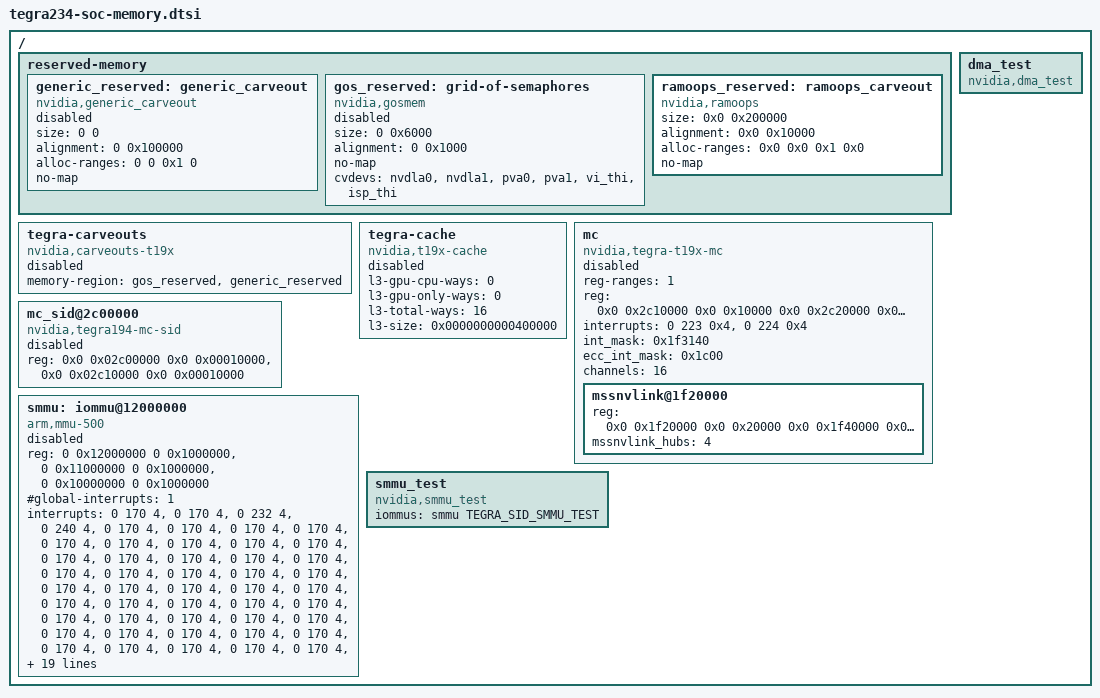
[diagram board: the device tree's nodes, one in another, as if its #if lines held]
/*
 * Copyright (c) 2018, NVIDIA CORPORATION.  All rights reserved.
 *
 * This program is free software; you can redistribute it and/or modify
 * it under the terms of the GNU General Public License as published by
 * the Free Software Foundation; version 2 of the License.
 *
 * This program is distributed in the hope that it will be useful, but WITHOUT
 * ANY WARRANTY; without even the implied warranty of MERCHANTABILITY or
 * FITNESS FOR A PARTICULAR PURPOSE.  See the GNU General Public License for
 * more details.
 *
 */

/ {
	reserved-memory {
		#address-cells = <2>;
		#size-cells = <2>;
		ranges;

		generic_reserved: generic_carveout {
			compatible = "nvidia,generic_carveout";
			size = <0 0>;
			alignment = <0 0x100000>;
			alloc-ranges = <0 0 0x1 0>;
			no-map;
			status = "disabled";
		};

		gos_reserved: grid-of-semaphores {
			compatible = "nvidia,gosmem";
			size = <0 0x6000>;
			alignment = <0 0x1000>;
			no-map;
			status = "disabled";
			cvdevs = <&nvdla0 &nvdla1 &pva0 &pva1 &vi_thi &isp_thi>;
		};

		ramoops_reserved: ramoops_carveout {
			compatible = "nvidia,ramoops";
			size = <0x0 0x200000>;
			alignment = <0x0 0x10000>;
			alloc-ranges = <0x0 0x0 0x1 0x0>;
			no-map;
		};

	};

	tegra-carveouts {
		compatible = "nvidia,carveouts-t19x";
		/* *************Note**************
		 * Zero sized memory regions has to be kept at the end of "memory-region"
		 * array. "memory-region" parser stops parsing other regions in the array
		 * once it finds Zero size "memory-region". Hence keep non zero sized
		 * "memory-region" before the zero sized ones.
		 */
		memory-region = <&gos_reserved &generic_reserved>;
		status = "disabled";
	};

	tegra-cache {
		compatible = "nvidia,t19x-cache";
		l3-gpu-cpu-ways = <0>;
		l3-gpu-only-ways = <0>;
		l3-total-ways = <16>;
		l3-size = /bits/ 64 <0x0000000000400000>; /* 4 MB */
		status = "disabled";
	};

	mc {
		#address-cells = <2>;
		#size-cells = <2>;
		compatible = "nvidia,tegra-t19x-mc";
		reg-ranges = <1>;
		reg	   = <0x0 0x2c10000 0x0 0x10000   /* MCB */
			      0x0 0x2c20000 0x0 0x10000   /* MC0 */
			      0x0 0x2c30000 0x0 0x10000   /* MC1 */
			      0x0 0x2c40000 0x0 0x10000   /* MC2 */
			      0x0 0x2c50000 0x0 0x10000   /* MC3 */
			      0x0 0x2b80000 0x0 0x10000   /* MC4 */
			      0x0 0x2b90000 0x0 0x10000   /* MC5 */
			      0x0 0x2ba0000 0x0 0x10000   /* MC6 */
			      0x0 0x2bb0000 0x0 0x10000   /* MC7 */
			      0x0 0x1700000 0x0 0x10000   /* MC8 */
			      0x0 0x1710000 0x0 0x10000   /* MC9 */
			      0x0 0x1720000 0x0 0x10000   /* MC10 */
			      0x0 0x1730000 0x0 0x10000   /* MC11 */
			      0x0 0x1740000 0x0 0x10000   /* MC12 */
			      0x0 0x1750000 0x0 0x10000   /* MC13 */
			      0x0 0x1760000 0x0 0x10000   /* MC14 */
			      0x0 0x1770000 0x0 0x10000   /* MC15 */
			      0x0 0x2C60000 0x0 0x10000   /* EMCB */
			      0x0 0x2c70000 0x0 0x10000   /* EMC0 */
			      0x0 0x2c80000 0x0 0x10000   /* EMC1 */
			      0x0 0x2c90000 0x0 0x10000   /* EMC2 */
			      0x0 0x2ca0000 0x0 0x10000   /* EMC3 */
			      0x0 0x2cb0000 0x0 0x10000   /* EMC4 */
			      0x0 0x2cc0000 0x0 0x10000   /* EMC5 */
			      0x0 0x2cd0000 0x0 0x10000   /* EMC6 */
			      0x0 0x2ce0000 0x0 0x10000   /* EMC7 */
			      0x0 0x1780000 0x0 0x10000   /* EMC8 */
			      0x0 0x1790000 0x0 0x10000   /* EMC9 */
			      0x0 0x17a0000 0x0 0x10000   /* EMC10 */
			      0x0 0x17b0000 0x0 0x10000   /* EMC11 */
			      0x0 0x17c0000 0x0 0x10000   /* EMC12 */
			      0x0 0x17d0000 0x0 0x10000   /* EMC13 */
			      0x0 0x17e0000 0x0 0x10000   /* EMC14 */
			      0x0 0x17f0000 0x0 0x10000>; /* EMC15 */

		interrupts = <0 223 0x4>, <0 224 0x4>;
		int_mask   = <0x1f3140>;
		ecc_int_mask   = <0x1c00>;

		channels   = <16>;
		ranges;
		status = "disabled";

		mssnvlink@1f20000 {
			reg = <0x0 0x1f20000 0x0 0x20000   /* MSSNVLINK 1: igpu0 link */
			       0x0 0x1f40000 0x0 0x20000   /* MSSNVLINK 2: igpu1 link */
			       0x0 0x1f60000 0x0 0x20000   /* MSSNVLINK 3: igpu2 link */
			       0x0 0x1f80000 0x0 0x20000>; /* MSSNVLINK 4: igpu3 link */
			mssnvlink_hubs = <4>;
		};
	};

	mc_sid@2c00000 {
		compatible = "nvidia,tegra194-mc-sid";
		reg = <0x0 0x02c00000 0x0 0x00010000>, /* MC_SID_BASE */
		      <0x0 0x02c10000 0x0 0x00010000>; /* MC_BASE */
		status = "disabled";
	};

#if LINUX_VERSION >= 414
	/* For Kernel version 4.14 onwards */
	smmu: iommu@12000000 {
		compatible = "arm,mmu-500";

		reg = <0 0x12000000 0 0x1000000>,
		      <0 0x11000000 0 0x1000000>,
		      <0 0x10000000 0 0x1000000>;

		#global-interrupts = <1>;
		interrupts = <0 170 4>,
			     <0 170 4>,
			     <0 232 4>,
			     <0 240 4>,
			     <0 170 4>,
			     <0 170 4>,
			     <0 170 4>,
			     <0 170 4>,
			     <0 170 4>,
			     <0 170 4>,
			     <0 170 4>,
			     <0 170 4>,
			     <0 170 4>,
			     <0 170 4>,
			     <0 170 4>,
			     <0 170 4>,
			     <0 170 4>,
			     <0 170 4>,
			     <0 170 4>,
			     <0 170 4>,
			     <0 170 4>,
			     <0 170 4>,
			     <0 170 4>,
			     <0 170 4>,
			     <0 170 4>,
			     <0 170 4>,
			     <0 170 4>,
			     <0 170 4>,
			     <0 170 4>,
			     <0 170 4>,
			     <0 170 4>,
			     <0 170 4>,
			     <0 170 4>,
			     <0 170 4>,
			     <0 170 4>,
			     <0 170 4>,
			     <0 170 4>,
			     <0 170 4>,
			     <0 170 4>,
			     <0 170 4>,
			     <0 170 4>,
			     <0 170 4>,
			     <0 170 4>,
			     <0 170 4>,
			     <0 170 4>,
			     <0 170 4>,
			     <0 170 4>,
			     <0 170 4>,
			     <0 170 4>,
			     <0 170 4>,
			     <0 170 4>,
			     <0 170 4>,
			     <0 170 4>,
			     <0 170 4>,
			     <0 170 4>,
			     <0 170 4>,
			     <0 170 4>,
			     <0 170 4>,
			     <0 170 4>,
			     <0 170 4>,
			     <0 170 4>,
			     <0 170 4>,
			     <0 170 4>,
			     <0 170 4>,
			     <0 170 4>,
			     <0 170 4>,
			     <0 170 4>,
			     <0 170 4>,
			     <0 170 4>,
			     <0 170 4>,
			     <0 170 4>,
			     <0 170 4>,
			     <0 170 4>,
			     <0 170 4>,
			     <0 170 4>,
			     <0 170 4>,
			     <0 170 4>,
			     <0 170 4>,
			     <0 170 4>,
			     <0 170 4>,
			     <0 170 4>,
			     <0 170 4>,
			     <0 170 4>,
			     <0 170 4>,
			     <0 170 4>,
			     <0 170 4>,
			     <0 170 4>,
			     <0 170 4>,
			     <0 170 4>,
			     <0 170 4>,
			     <0 170 4>,
			     <0 170 4>,
			     <0 170 4>,
			     <0 170 4>,
			     <0 170 4>,
			     <0 170 4>,
			     <0 170 4>,
			     <0 170 4>,
			     <0 170 4>,
			     <0 170 4>,
			     <0 170 4>,
			     <0 170 4>,
			     <0 170 4>,
			     <0 170 4>,
			     <0 170 4>,
			     <0 170 4>,
			     <0 170 4>,
			     <0 170 4>,
			     <0 170 4>,
			     <0 170 4>,
			     <0 170 4>,
			     <0 170 4>,
			     <0 170 4>,
			     <0 170 4>,
			     <0 170 4>,
			     <0 170 4>,
			     <0 170 4>,
			     <0 170 4>,
			     <0 170 4>,
			     <0 170 4>,
			     <0 170 4>,
			     <0 170 4>,
			     <0 170 4>,
			     <0 170 4>,
			     <0 170 4>,
			     <0 170 4>,
			     <0 170 4>,
			     <0 170 4>,
			     <0 170 4>;
		stream-match-mask = <0x7F80>;
		#iommu-cells = <1>;
		iso-smmu-id = <2>;

		status = "disabled";
	};
#else
	/* For Kernel version 4.9 */
	smmu: iommu@12000000 {
		compatible = "t19x,arm,mmu-500";

		reg = <0x0 0x12000000 0x0 0x01000000>, /* SMMU0 16MB */
		      <0x0 0x11000000 0x0 0x01000000>, /* SMMU1 16MB */
		      <0x0 0x10000000 0x0 0x01000000>; /* SMMU2 16MB */

		#global-interrupts = <6>;
		interrupts = <0 170 4>,
			     <0 171 4>,
			     <0 232 4>,
			     <0 233 4>,
			     <0 240 4>,
			     <0 241 4>;

		#iommu-cells = <1>;
		iso-smmu-id = <2>;

		status = "disabled";

		/* Note: Keep domain and address space in alphabetical order */
		domains {
			aon_domain {
				address-space = <&common_as>;
				sid-list = <TEGRA_SID_AON>;
			};
			ape_domain {
				address-space = <&ape_as>;
				sid-list = <TEGRA_SID(APE)
					    TEGRA_SID(EQOS)>;
			};
			bpmp_domain {
				address-space = <&common_as>;
				sid-list = <TEGRA_SID_BPMP>;
			};
			gpcdma_domain {
				address-space = <&common_as>;
				sid-list = <TEGRA_SID_GPCDMA_0>;
			};
			hda_domain {
				address-space = <&common_as>;
				sid-list = <TEGRA_SID_HDA>;
			};
			host1x_domain {
				address-space = <&host1x_as>;
				sid-list = <TEGRA_SID(HC)>;
			};
			host1x_client_domain {
				address-space = <&host1x_client_as>;
				sid-list = <TEGRA_SID(VIC)
					    TEGRA_SID(NVDEC)
					    TEGRA_SID(NVENC)
					    TEGRA_SID(NVJPG)
					    TEGRA_SID(NVDLA0)
					    TEGRA_SID(NVDLA1)
					    TEGRA_SID(NVENC1)
					    TEGRA_SID(NVDEC1)
					    TEGRA_SID(TSEC)
					    TEGRA_SID(TSECB)>;
			};
			host1x0_domain {
				address-space = <&host1x_client_as>;
				sid-list = <TEGRA_SID_HOST1X_CTX0>;
			};
			host1x1_domain {
				address-space = <&host1x_client_as>;
				sid-list = <TEGRA_SID_HOST1X_CTX1>;
			};
			host1x2_domain {
				address-space = <&host1x_client_as>;
				sid-list = <TEGRA_SID_HOST1X_CTX2>;
			};
			host1x3_domain {
				address-space = <&host1x_client_as>;
				sid-list = <TEGRA_SID_HOST1X_CTX3>;
			};
			host1x4_domain {
				address-space = <&host1x_client_as>;
				sid-list = <TEGRA_SID_HOST1X_CTX4>;
			};
			host1x5_domain {
				address-space = <&host1x_client_as>;
				sid-list = <TEGRA_SID_HOST1X_CTX5>;
			};
			host1x6_domain {
				address-space = <&host1x_client_as>;
				sid-list = <TEGRA_SID_HOST1X_CTX6>;
			};
			host1x7_domain {
				address-space = <&host1x_client_as>;
				sid-list = <TEGRA_SID_HOST1X_CTX7>;
			};
			isp_domain {
				address-space = <&common_as>;
				sid-list = <TEGRA_SID(ISP)>;
			};
			nvdisplay_domain {
				address-space = <&nvdisplay_as>;
				sid-list = <TEGRA_SID(NVDISPLAY)>;
			};
			pcie0_domain {
				address-space = <&pcie0_as>;
				sid-list = <TEGRA_SID_PCIE0>;
			};
			pcie1_domain {
				address-space = <&pcie1_as>;
				sid-list = <TEGRA_SID_PCIE1>;
			};
			pcie2_domain {
				address-space = <&pcie2_as>;
				sid-list = <TEGRA_SID_PCIE2>;
			};
			pcie3_domain {
				address-space = <&pcie3_as>;
				sid-list = <TEGRA_SID_PCIE3>;
			};
			pcie4_domain {
				address-space = <&pcie4_as>;
				sid-list = <TEGRA_SID_PCIE4>;
			};
			pcie5_domain {
				address-space = <&pcie5_as>;
				sid-list = <TEGRA_SID_PCIE5>;
			};
			pva0_domain {
				address-space = <&pva_as>;
				sid-list = <TEGRA_SID(PVA0)>;
			};
			pva1_domain {
				address-space = <&pva_as>;
				sid-list = <TEGRA_SID(PVA1)>;
			};
			sce_domain {
				address-space = <&common_as>;
				sid-list = <TEGRA_SID_SCE>;
			};
			rce_domain {
				address-space = <&camera_vm1_as>;
				sid-list = <TEGRA_SID(RCE)>;
			};
			sata2_domain {
				address-space = <&common_as>;
				sid-list = <TEGRA_SID_SATA2>;
			};
			sdmmc1a_domain {
				address-space = <&common_as>;
				sid-list = <TEGRA_SID_SDMMC1A>;
			};
			sdmmc3a_domain {
				address-space = <&common_as>;
				sid-list = <TEGRA_SID_SDMMC3A>;
			};
			sdmmc4a_domain {
				address-space = <&common_as>;
				sid-list = <TEGRA_SID_SDMMC4A>;
			};
			se_domain {
				address-space = <&se_client_as>;
				sid-list = <TEGRA_SID(SE)
					    TEGRA_SID(SE1)
					    TEGRA_SID(SE2)
					    TEGRA_SID(SE3)>;
			};
			smmu_test_domain {
				address-space = <&common_as>;
				sid-list = <TEGRA_SID_SMMU_TEST>;
			};
			ufshci_domain {
				address-space = <&common_as>;
				sid-list = <TEGRA_SID_UFSHC>;
			};
			vi_domain {
				address-space = <&common_as>;
				sid-list = <TEGRA_SID(VI)>;
			};
			xusb_dev_domain {
				address-space = <&common_as>;
				sid-list = <TEGRA_SID_XUSB_DEV>;
			};
			xusb_host_domain {
				address-space = <&common_as>;
				sid-list = <TEGRA_SID_XUSB_HOST>;
			};
			xusb_host_vf0_domain {
				address-space = <&common_as>;
				sid-list = <TEGRA_SID_XUSB_VF0>;
			};
			xusb_host_vf1_domain {
				address-space = <&common_as>;
				sid-list = <TEGRA_SID_XUSB_VF1>;
			};
			xusb_host_vf2_domain {
				address-space = <&common_as>;
				sid-list = <TEGRA_SID_XUSB_VF2>;
			};
			xusb_host_vf3_domain {
				address-space = <&common_as>;
				sid-list = <TEGRA_SID_XUSB_VF3>;
			};
		};

		address-space-prop {
			ape_as: ape {
				iova-start = <0x0 0x40000000>;
				iova-size = <0x0 0x20000000>;
				alignment = <0xFFFFF>;
				num-pf-page = <0>;
				gap-page = <1>;
			};
			camera_vm0_as: camera_vm0 {
				iova-start = <0x0 0x80000000>;
				iova-size = <0x0 0x20000000>;
				alignment = <0xFFFFF>;
				num-pf-page = <0>;
				gap-page = <1>;
			};
			camera_vm1_as: camera_vm1 {
				iova-start = <0x0 0xA0000000>;
				iova-size = <0x0 0x20000000>;
				alignment = <0xFFFFF>;
				num-pf-page = <0>;
				gap-page = <1>;
			};
			common_as: common {
				iova-start = <0x0 0x80000000>;
				iova-size = <0x0 0x7FF00000>;
				alignment = <0xFFFFF>;
				num-pf-page = <0>;
				gap-page = <1>;
			};
			host1x_as: host1x {
				iova-start = <0x0 0x1000>;
				iova-size = <0x0 0xFFFFEFFF>;
				alignment = <0xFFFFF>;
				num-pf-page = <0>;
				gap-page = <1>;
			};
			host1x_client_as: host1x_client {
				iova-start = <0x0 0x1000>;
				iova-size = <0x1F 0xFFFFF000>;
				alignment = <0xFFFFF>;
				num-pf-page = <0>;
				gap-page = <1>;
			};
			nvdisplay_as: nvdisplay {
				iova-start = <0x0 0x1000>;
				iova-size = <0x0 0xFFFFEFFF>;
				alignment = <0xFFFFF>;
				num-pf-page = <0>;
				gap-page = <1>;
			};
			pcie0_as: pcie0 {
				iova-start = <0x0 0x80000000>;
				iova-size = <0x4 0x7FFFFFFF>;
				alignment = <0xFFFFF>;
				num-pf-page = <0>;
				gap-page = <1>;
			};
			pcie1_as: pcie1 {
				iova-start = <0x0 0x80000000>;
				iova-size = <0x0 0xFFFFFFFF>;
				alignment = <0xFFFFF>;
				num-pf-page = <0>;
				gap-page = <1>;
			};
			pcie2_as: pcie2 {
				iova-start = <0x0 0x80000000>;
				iova-size = <0x0 0xFFFFFFFF>;
				alignment = <0xFFFFF>;
				num-pf-page = <0>;
				gap-page = <1>;
			};
			pcie3_as: pcie3 {
				iova-start = <0x0 0x80000000>;
				iova-size = <0x0 0xFFFFFFFF>;
				alignment = <0xFFFFF>;
				num-pf-page = <0>;
				gap-page = <1>;
			};
			pcie4_as: pcie4 {
				iova-start = <0x0 0x80000000>;
				iova-size = <0x4 0x7FFFFFFF>;
				alignment = <0xFFFFF>;
				num-pf-page = <0>;
				gap-page = <1>;
			};
			pcie5_as: pcie5 {
				iova-start = <0x0 0x80000000>;
				iova-size = <0x4 0x7FFFFFFF>;
				alignment = <0xFFFFF>;
				num-pf-page = <0>;
				gap-page = <1>;
			};
			/* Modify pva kernel code for any iova-start change*/
			pva_as: pva0 {
				iova-start = <0x0 0x80000000>;
				iova-size = <0x0 0x7FFFFFFF>;
				alignment = <0xFFFFF>;
				num-pf-page = <0>;
				gap-page = <1>;
			};
			se_client_as: se {
				iova-start = <0x0 0x1000>;
				iova-size = <0x0 0xFFFFEFFF>;
				alignment = <0xFFFFF>;
				num-pf-page = <0>;
				gap-page = <1>;
			};
		};
	};
#endif

	smmu_test: smmu_test {
		compatible = "nvidia,smmu_test";
		iommus = <&smmu TEGRA_SID_SMMU_TEST>;
	};

	dma_test: dma_test {
		compatible = "nvidia,dma_test";
	};
};
